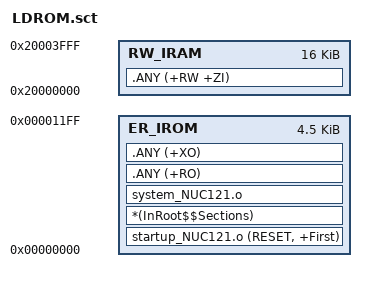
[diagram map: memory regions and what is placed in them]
; *************************************************************
; *** Scatter-Loading Description File generated by uVision ***
; *************************************************************

LR_IROM 0x00000000 0x00001200  {    ; load region size_region
	ER_IROM 0x00000000 0x00001200  {  ; load address = execution address
		startup_NUC121.o (RESET, +First)
		*(InRoot$$Sections)
		system_NUC121.o
		.ANY (+RO)
		.ANY (+XO)
	}
	
	RW_IRAM 0x20000000 0x00004000  {  ; RW data
		.ANY (+RW +ZI)
	}
}
